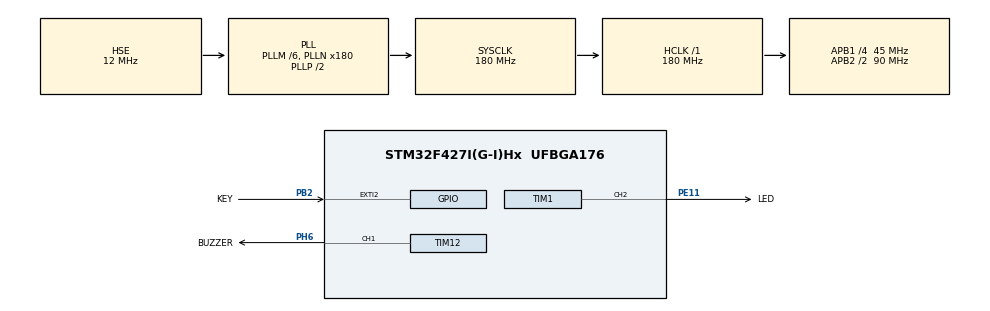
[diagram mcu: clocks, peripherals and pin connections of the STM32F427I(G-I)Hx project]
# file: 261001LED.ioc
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Mcu.Family=STM32F4
Mcu.Name=STM32F427I(G-I)Hx
Mcu.Package=UFBGA176
NVIC.EXTI2_IRQn=true\:2\:0\:true\:false\:true\:true\:true\:true
NVIC.PriorityGroup=NVIC_PRIORITYGROUP_4
PA13.Mode=Serial_Wire
PA13.Signal=SYS_JTMS-SWDIO
PA14.Mode=Serial_Wire
PA14.Signal=SYS_JTCK-SWCLK
PB2/BOOT1.GPIO_Label=KEY
PB2/BOOT1.GPIO_PuPd=GPIO_PULLDOWN
PB2/BOOT1.Signal=GPXTI2
PE11.GPIO_Label=LED
PE11.Signal=S_TIM1_CH2
PH0/OSC_IN.Mode=HSE-External-Oscillator
PH0/OSC_IN.Signal=RCC_OSC_IN
PH1/OSC_OUT.Mode=HSE-External-Oscillator
PH1/OSC_OUT.Signal=RCC_OSC_OUT
PH6.GPIO_Label=BUZZER
PH6.GPIO_Speed=GPIO_SPEED_FREQ_HIGH
PH6.Signal=S_TIM12_CH1
ProjectManager.HeapSize=0x200
ProjectManager.StackSize=0x400
ProjectManager.TargetToolchain=MDK-ARM V5.32
RCC.48MHZClocksFreq_Value=90000000
RCC.AHBFreq_Value=180000000
RCC.APB1CLKDivider=RCC_HCLK_DIV4
RCC.APB1Freq_Value=45000000
RCC.APB1TimFreq_Value=90000000
RCC.APB2CLKDivider=RCC_HCLK_DIV2
RCC.APB2Freq_Value=90000000
RCC.APB2TimFreq_Value=180000000
RCC.CortexFreq_Value=180000000
RCC.HCLKFreq_Value=180000000
RCC.HSE_VALUE=12000000
RCC.HSI_VALUE=16000000
RCC.LSE_VALUE=32768
RCC.PLLM=6
RCC.PLLN=180
RCC.PLLSourceVirtual=RCC_PLLSOURCE_HSE
RCC.SYSCLKFreq_VALUE=180000000
RCC.SYSCLKSource=RCC_SYSCLKSOURCE_PLLCLK
RCC.VCOOutputFreq_Value=360000000
SH.S_TIM12_CH1.0=TIM12_CH1,PWM Generation1 CH1
SH.S_TIM1_CH2.0=TIM1_CH2,PWM Generation2 CH2
TIM1.Channel-PWM\ Generation2\ CH2=TIM_CHANNEL_2
TIM1.OCMode_PWM-PWM\ Generation2\ CH2=TIM_OCMODE_PWM2
TIM1.Period=10000-1
TIM1.Prescaler=180-1
TIM1.Pulse-PWM\ Generation2\ CH2=500
TIM12.Channel-PWM\ Generation1\ CH1=TIM_CHANNEL_1
TIM12.Period=1923-1
TIM12.Prescaler=180-1
TIM12.Pulse-PWM\ Generation1\ CH1=500
VP_TIM12_VS_ClockSourceINT.Mode=Internal
VP_TIM1_VS_ClockSourceINT.Mode=Internal
board=custom

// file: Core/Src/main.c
/* USER CODE BEGIN Header */
/**
  ******************************************************************************
  * @file           : main.c
  * @brief          : Main program body
  ******************************************************************************
  * @attention
  *
  * Copyright (c) 2026 STMicroelectronics.
  * All rights reserved.
  *
  * This software is licensed under terms that can be found in the LICENSE file
  * in the root directory of this software component.
  * If no LICENSE file comes with this software, it is provided AS-IS.
  *
  ******************************************************************************
  */
/* USER CODE END Header */
#include "main.h"
#include "tim.h"
#include "gpio.h"

/* USER CODE BEGIN Includes */
#include "stdint.h"
/* USER CODE END Includes */

void SystemClock_Config(void);

/* USER CODE BEGIN 0 */
volatile uint8_t requested_mode=0;
volatile uint8_t first_enter=1;

uint32_t last;
int8_t duty_direction=10;
uint32_t pulse = 0;

// void setTone(uint32_t freq,uint32_t duration) {
//   uint32_t period = 90000000/(freq*180);
//   uint32_t pulse=period/200;
//   __HAL_TIM_SET_AUTORELOAD(&htim12,period-1);
//   __HAL_TIM_SET_COMPARE(&htim12,TIM_CHANNEL_1,pulse);
//   HAL_Delay(duration);
// }
void UpdateLed(uint32_t now) {

  if(requested_mode==0) {
    pulse=0;
    if (first_enter==1) {
      __HAL_TIM_SET_COMPARE(&htim1, TIM_CHANNEL_2, pulse);
    }
  }
  else if (requested_mode==1) {
    if (first_enter==1) {
      first_enter=0;
      pulse=0;
      duty_direction=10;
    }
    if (now-last>=10) {
      last=now;
      pulse+=duty_direction;
      if (pulse>=10000 && duty_direction==10) {
        pulse = 10000;
        duty_direction = -10;
      }
      else if (pulse<=0 && duty_direction==-10) {
        pulse = 0;
        duty_direction = 10;
      }
      __HAL_TIM_SET_COMPARE(&htim1, TIM_CHANNEL_2, pulse);
    }
  }
  else {
    if (now-last>=500) {
      last=now;
      pulse=pulse ? 0:500;
      __HAL_TIM_SET_COMPARE(&htim1, TIM_CHANNEL_2, pulse);
    }
  }
}

/* USER CODE END 0 */

int main(void)
{

  /* MCU Configuration--------------------------------------------------------*/

  /* Reset of all peripherals, Initializes the Flash interface and the Systick. */
  HAL_Init();

  /* Configure the system clock */
  SystemClock_Config();

  /* Initialize all configured peripherals */
  MX_GPIO_Init();
  MX_TIM1_Init();
  MX_TIM12_Init();
  /* USER CODE BEGIN 2 */
  HAL_TIM_Base_Start(&htim1);
  //HAL_TIM_Base_Start_IT(&htim1);
  //HAL_TIM_Base_Start(&htim12);
  HAL_TIM_PWM_Start(&htim1, TIM_CHANNEL_2);
  //HAL_TIM_PWM_Start(&htim12, TIM_CHANNEL_1);
  last = HAL_GetTick();

  /* USER CODE END 2 */

  /* Infinite loop */
  /* USER CODE BEGIN WHILE */
  while (1){
		uint32_t now=HAL_GetTick();
    UpdateLed(now);
    /* USER CODE END WHILE */

  }
}

void SystemClock_Config(void)
{
  RCC_OscInitTypeDef RCC_OscInitStruct = {0};
  RCC_ClkInitTypeDef RCC_ClkInitStruct = {0};

  /** Configure the main internal regulator output voltage
  */
  __HAL_RCC_PWR_CLK_ENABLE();
  __HAL_PWR_VOLTAGESCALING_CONFIG(PWR_REGULATOR_VOLTAGE_SCALE1);

  /** Initializes the RCC Oscillators according to the specified parameters
  * in the RCC_OscInitTypeDef structure.
  */
  RCC_OscInitStruct.OscillatorType = RCC_OSCILLATORTYPE_HSE;
  RCC_OscInitStruct.HSEState = RCC_HSE_ON;
  RCC_OscInitStruct.PLL.PLLState = RCC_PLL_ON;
  RCC_OscInitStruct.PLL.PLLSource = RCC_PLLSOURCE_HSE;
  RCC_OscInitStruct.PLL.PLLM = 6;
  RCC_OscInitStruct.PLL.PLLN = 180;
  RCC_OscInitStruct.PLL.PLLP = RCC_PLLP_DIV2;
  RCC_OscInitStruct.PLL.PLLQ = 4;
  if (HAL_RCC_OscConfig(&RCC_OscInitStruct) != HAL_OK)
  {
    Error_Handler();
  }

  /** Activate the Over-Drive mode
  */
  if (HAL_PWREx_EnableOverDrive() != HAL_OK)
  {
    Error_Handler();
  }

  /** Initializes the CPU, AHB and APB buses clocks
  */
  RCC_ClkInitStruct.ClockType = RCC_CLOCKTYPE_HCLK|RCC_CLOCKTYPE_SYSCLK
                              |RCC_CLOCKTYPE_PCLK1|RCC_CLOCKTYPE_PCLK2;
  RCC_ClkInitStruct.SYSCLKSource = RCC_SYSCLKSOURCE_PLLCLK;
  RCC_ClkInitStruct.AHBCLKDivider = RCC_SYSCLK_DIV1;
  RCC_ClkInitStruct.APB1CLKDivider = RCC_HCLK_DIV4;
  RCC_ClkInitStruct.APB2CLKDivider = RCC_HCLK_DIV2;

  if (HAL_RCC_ClockConfig(&RCC_ClkInitStruct, FLASH_LATENCY_5) != HAL_OK)
  {
    Error_Handler();
  }
}

/* USER CODE BEGIN 4 */
// void HAL_GPIO_EXTI_Callback(uint16_t GPIO_Pin) {
//   if (GPIO_Pin == GPIO_PIN_2) {
//     HAL_IWDG_Refresh(&hiwdg);
//   }
// }
/* USER CODE END 4 */

void Error_Handler(void)
{
  __disable_irq();
  while (1)
  {
  }
}
